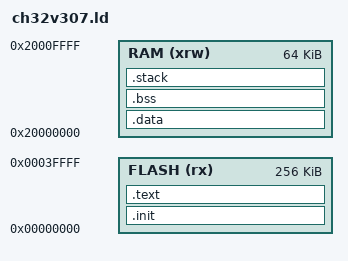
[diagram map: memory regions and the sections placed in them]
ENTRY(_start)

__stack_size = 2048;

MEMORY
{
    FLASH (rx)  : ORIGIN = 0x00000000, LENGTH = 256K
    RAM   (xrw) : ORIGIN = 0x20000000, LENGTH = 64K
}

SECTIONS
{
    .init :
    {
        KEEP(*(.init))
    } > FLASH

    .text :
    {
        . = ALIGN(4);
        *(.text)
        *(.text.*)
        *(.rodata)
        *(.rodata*)
        . = ALIGN(4);
        _etext = .;
    } > FLASH

    .data : AT(_etext)
    {
        . = ALIGN(4);
        _data_vma = .;
        *(.data)
        *(.data.*)
        . = ALIGN(8);
        PROVIDE(__global_pointer$ = . + 0x800);
        *(.sdata)
        *(.sdata.*)
        . = ALIGN(4);
        _edata = .;
    } > RAM

    _data_lma = LOADADDR(.data);

    .bss :
    {
        . = ALIGN(4);
        _sbss = .;
        *(.sbss*)
        *(.bss)
        *(.bss.*)
        *(COMMON)
        . = ALIGN(4);
        _ebss = .;
    } > RAM

    .stack ORIGIN(RAM) + LENGTH(RAM) - __stack_size :
    {
        . = ALIGN(4);
        _susrstack = .;
        . = . + __stack_size;
        _eusrstack = .;
    } > RAM
}
